# PIC32MX575F512L register map
Vendor: Microchip
Registers are 32-bit, read-write, reset 0x0 unless marked. A register's access mark holds for its fields unless they carry their own. Addresses are absolute, and some are shared; only a register's first bit layout is shown; [hi:lo] are bit positions; {n}, {i} and the like mark numbered series.

## CVR
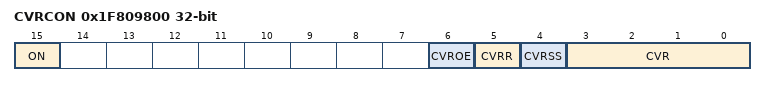
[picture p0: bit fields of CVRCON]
0x1F809800 CVRCON
  [15] ON, [6] CVROE, [5] CVRR, [4] CVRSS, [3:0] CVR

## CMP1
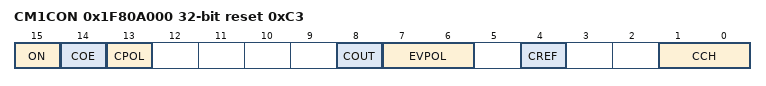
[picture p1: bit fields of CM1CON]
0x1F80A000 CM1CON reset 0xC3
  [15] ON, [14] COE, [13] CPOL, [8] COUT, [7:6] EVPOL, [4] CREF, [1:0] CCH

## CMP2
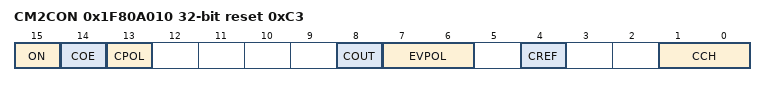
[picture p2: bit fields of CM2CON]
0x1F80A010 CM2CON reset 0xC3
  [15] ON, [14] COE, [13] CPOL, [8] COUT, [7:6] EVPOL, [4] CREF, [1:0] CCH

## cmp_control_pb
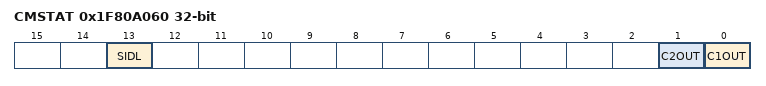
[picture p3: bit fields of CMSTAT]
0x1F80A060 CMSTAT
  [13] SIDL, [1] C2OUT ro, [0] C1OUT ro

## OSC
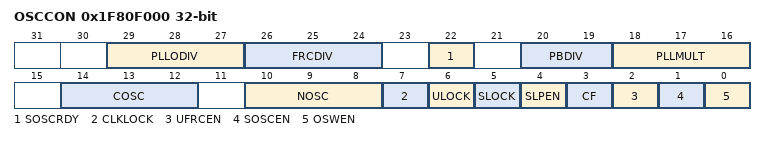
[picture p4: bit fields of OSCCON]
0x1F80F000 OSCCON reset not defined — (power-on value --qqq001-00qqqqq-000-qqq000000q0)
  [29:27] PLLODIV, [26:24] FRCDIV, [22] SOSCRDY, [20:19] PBDIV, [18:16] PLLMULT, [14:12] COSC, [10:8] NOSC, [7] CLKLOCK, [6] ULOCK, [5] SLOCK, [4] SLPEN, [3] CF, [2] UFRCEN, [1] SOSCEN, [0] OSWEN
0x1F80F010 OSCTUN
  [5:0] TUN

## CFG
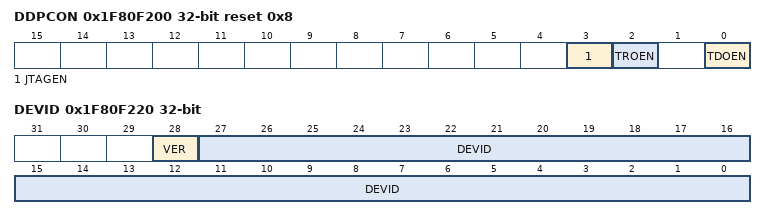
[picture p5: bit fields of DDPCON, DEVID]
0x1F80F200 DDPCON reset 0x8
  [3] JTAGEN, [2] TROEN, [0] TDOEN
0x1F80F220 DEVID ro reset not defined — (power-on value xxxxxxxxxxxxxxxxxxxxxxxxxxxxxxxx)
  [28] VER, [27:0] DEVID
0x1F80F230 SYSKEY ro reset not defined — (power-on value xxxxxxxxxxxxxxxxxxxxxxxxxxxxxxxx)

## NVM
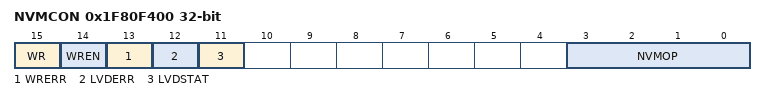
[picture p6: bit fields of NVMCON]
0x1F80F400 NVMCON
  [15] WR, [14] WREN, [13] WRERR ro, [12] LVDERR ro, [11] LVDSTAT ro, [3:0] NVMOP
0x1F80F410 NVMKEY wo
0x1F80F420 NVMADDR
0x1F80F430 NVMDATA
0x1F80F440 NVMSRCADDR

## RCON
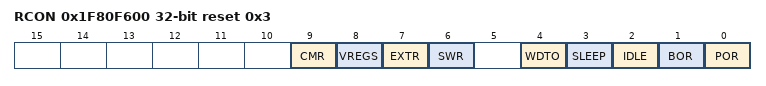
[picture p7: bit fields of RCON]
0x1F80F600 RCON reset 0x3
  [9] CMR, [8] VREGS, [7] EXTR, [6] SWR, [4] WDTO, [3] SLEEP, [2] IDLE, [1] BOR, [0] POR
0x1F80F610 RSWRST
  [0] SWRST

## CAN1
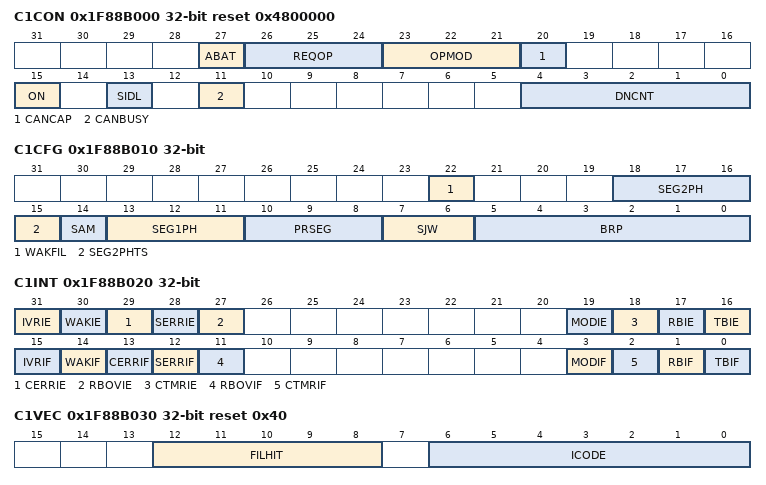
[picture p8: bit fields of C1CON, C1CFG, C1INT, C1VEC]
0x1F88B000 C1CON reset 0x4800000
  [27] ABAT — (can only be set)
  [26:24] REQOP
  [23:21] OPMOD ro
  [20] CANCAP
  [15] ON
  [13] SIDL
  [11] CANBUSY ro
  [4:0] DNCNT
0x1F88B010 C1CFG
  [22] WAKFIL, [18:16] SEG2PH, [15] SEG2PHTS, [14] SAM, [13:11] SEG1PH, [10:8] PRSEG, [7:6] SJW, [5:0] BRP
0x1F88B020 C1INT
  [31] IVRIE, [30] WAKIE, [29] CERRIE, [28] SERRIE, [27] RBOVIE, [19] MODIE, [18] CTMRIE, [17] RBIE, [16] TBIE, [15] IVRIF, [14] WAKIF, [13] CERRIF, [12] SERRIF, [11] RBOVIF, [3] MODIF, [2] CTMRIF, [1] RBIF, [0] TBIF
0x1F88B030 C1VEC ro reset 0x40
  [12:8] FILHIT, [6:0] ICODE
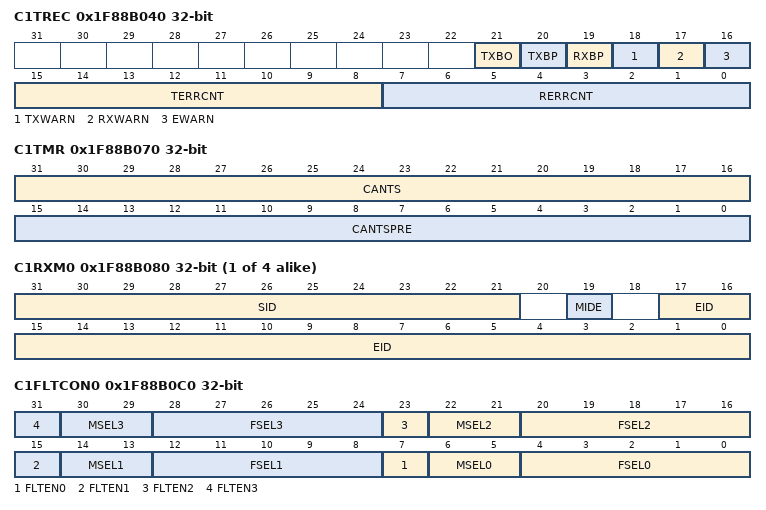
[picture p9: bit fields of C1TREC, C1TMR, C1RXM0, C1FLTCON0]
0x1F88B040 C1TREC ro
  [21] TXBO, [20] TXBP, [19] RXBP, [18] TXWARN, [17] RXWARN, [16] EWARN, [15:8] TERRCNT, [7:0] RERRCNT
0x1F88B050 C1FSTAT ro
  [31:0] FIFOIP
0x1F88B060 C1RXOVF ro
  [31:0] RXOVF
0x1F88B070 C1TMR
  [31:16] CANTS, [15:0] CANTSPRE
{0x1F88B080+0x10*i} C1RXM{i} (i=0..3)
  [31:21] SID, [19] MIDE, [17:0] EID
0x1F88B0C0 C1FLTCON0
  [8n+7] FLTEN{n} (n=0..3), [8n+6:8n+5] MSEL{n} (n=0..3), [8n+4:8n] FSEL{n} (n=0..3)
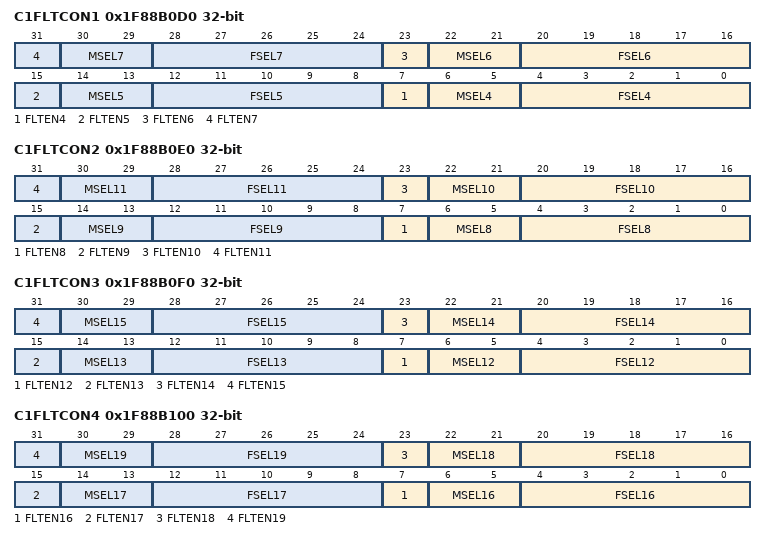
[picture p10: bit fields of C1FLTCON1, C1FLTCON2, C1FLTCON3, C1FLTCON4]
0x1F88B0D0 C1FLTCON1
  [8n-25] FLTEN{n} (n=4..7), [8n-26:8n-27] MSEL{n} (n=4..7), [8n-28:8n-32] FSEL{n} (n=4..7)
0x1F88B0E0 C1FLTCON2
  [8n-57] FLTEN{n} (n=8..11), [8n-58:8n-59] MSEL{n} (n=8..11), [8n-60:8n-64] FSEL{n} (n=8..11)
0x1F88B0F0 C1FLTCON3
  [8n-89] FLTEN{n} (n=12..15), [8n-90:8n-91] MSEL{n} (n=12..15), [8n-92:8n-96] FSEL{n} (n=12..15)
0x1F88B100 C1FLTCON4
  [8n-121] FLTEN{n} (n=16..19), [8n-122:8n-123] MSEL{n} (n=16..19), [8n-124:8n-128] FSEL{n} (n=16..19)
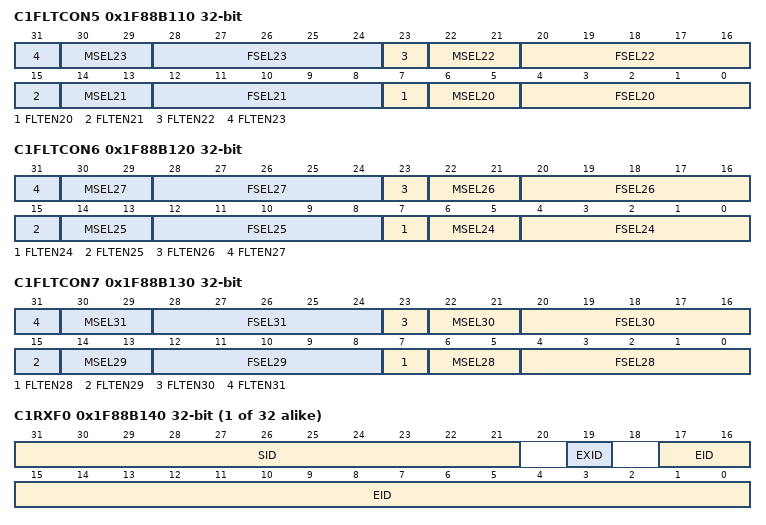
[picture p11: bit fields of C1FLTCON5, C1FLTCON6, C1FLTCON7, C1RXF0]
0x1F88B110 C1FLTCON5
  [8n-153] FLTEN{n} (n=20..23), [8n-154:8n-155] MSEL{n} (n=20..23), [8n-156:8n-160] FSEL{n} (n=20..23)
0x1F88B120 C1FLTCON6
  [8n-185] FLTEN{n} (n=24..27), [8n-186:8n-187] MSEL{n} (n=24..27), [8n-188:8n-192] FSEL{n} (n=24..27)
0x1F88B130 C1FLTCON7
  [8n-217] FLTEN{n} (n=28..31), [8n-218:8n-219] MSEL{n} (n=28..31), [8n-220:8n-224] FSEL{n} (n=28..31)
{0x1F88B140+0x10*i} C1RXF{i} reset not defined (i=0..31) — (power-on value xxxxxxxxxxx0x0xxxxxxxxxxxxxxxxxx)
  [31:21] SID, [19] EXID, [17:0] EID
0x1F88B340 C1FIFOBA
  [31:2] FIFOBA
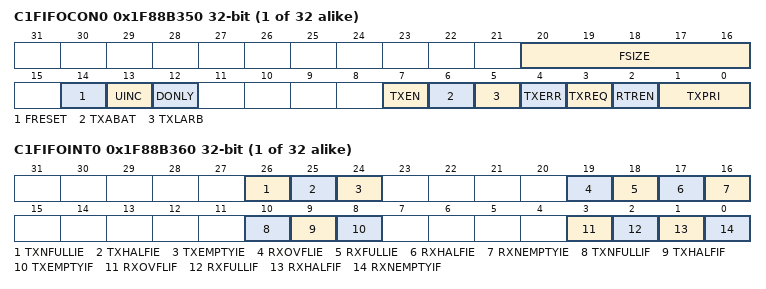
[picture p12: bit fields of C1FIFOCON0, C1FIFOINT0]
{0x1F88B350+0x40*i} C1FIFOCON{i} (i=0..31)
  [20:16] FSIZE, [14] FRESET, [13] UINC, [12] DONLY, [7] TXEN, [6] TXABAT, [5] TXLARB, [4] TXERR, [3] TXREQ, [2] RTREN, [1:0] TXPRI
{0x1F88B360+0x40*i} C1FIFOINT{i} (i=0..31)
  [26] TXNFULLIE, [25] TXHALFIE, [24] TXEMPTYIE, [19] RXOVFLIE, [18] RXFULLIE, [17] RXHALFIE, [16] RXNEMPTYIE, [10] TXNFULLIF ro, [9] TXHALFIF ro, [8] TXEMPTYIF ro, [3] RXOVFLIF, [2] RXFULLIF ro, [1] RXHALFIF ro, [0] RXNEMPTYIF ro
{0x1F88B370+0x40*i} C1FIFOUA{i} ro reset not defined (i=0..31) — (power-on value xxxxxxxxxxxxxxxxxxxxxxxxxxxxxx00)
  [31:2] FIFOUA
{0x1F88B380+0x40*i} C1FIFOCI{i} ro (i=0..31)
  [4:0] CFIFOCI
